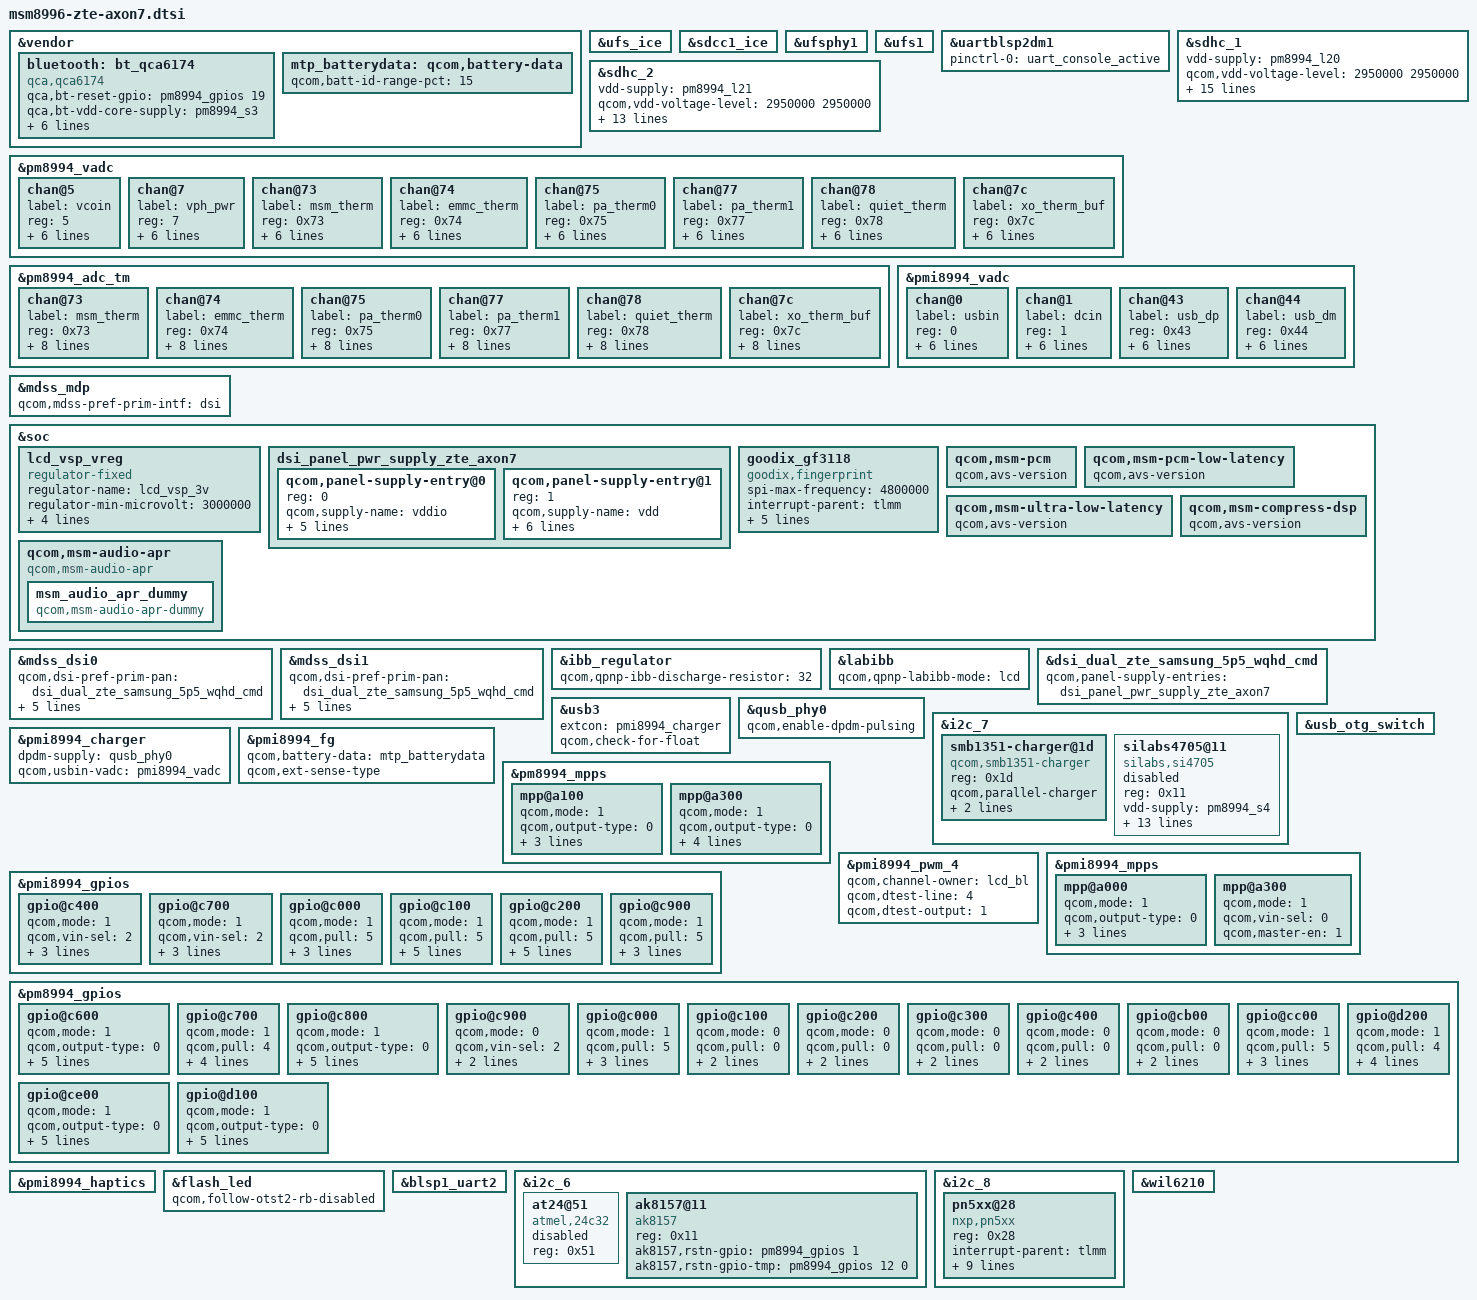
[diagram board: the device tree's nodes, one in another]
/* Copyright (c) 2015-2019, The Linux Foundation. All rights reserved.
 * Copyright (C) 2016 ZTE Corporation.
 *
 * This program is free software; you can redistribute it and/or modify
 * it under the terms of the GNU General Public License version 2 and
 * only version 2 as published by the Free Software Foundation.
 *
 * This program is distributed in the hope that it will be useful,
 * but WITHOUT ANY WARRANTY; without even the implied warranty of
 * MERCHANTABILITY or FITNESS FOR A PARTICULAR PURPOSE.  See the
 * GNU General Public License for more details.
 */

/*
 * ZTE Axon 7 (A2017G, ailsa_ii) board.
 *
 * ZTE built the Axon 7 board file by editing the CAF msm8996-mtp.dtsi of
 * their 3.18 kernel. This file is the 4.4 CAF msm8996-mtp.dtsi with the same
 * ZTE edits applied, so it can be compared with both. Left out from the MTP
 * file: the overrides for CAF reference panels and the TDM audio interfaces
 * (not used on this board), and the WCD9335 sound card (no WCD9335 here).
 * ZTE's changes to the shared SoC/PMIC files are in
 * msm8996-zte-axon7-common.dtsi.
 */

#include <dt-bindings/clock/msm-clocks-8996.h>
#include "msm8996-camera-sensor-zte-axon7.dtsi"
#include "msm8996-zte-axon7-typec.dtsi"
#include "msm8996-wsa881x.dtsi"

&vendor {
	bluetooth: bt_qca6174 {
		compatible = "qca,qca6174";
		qca,bt-reset-gpio = <&pm8994_gpios 19 0>; /* BT_EN */
		qca,bt-vdd-core-supply = <&pm8994_s3>;
		qca,bt-vdd-pa-supply = <&rome_vreg>;
		qca,bt-vdd-io-supply = <&pm8994_s4>;
		qca,bt-vdd-xtal-supply = <&pm8994_l30>;
		qca,bt-chip-pwd-voltage-level = <1300000 1300000>;
		qca,bt-vdd-io-voltage-level = <1800000 1800000>;
		qca,bt-vdd-xtal-voltage-level = <1800000 1800000>;
	};
};

&ufs_ice {
        status = "ok";
};

&sdcc1_ice {
        status = "ok";
};

&ufsphy1 {
	status = "ok";
};

&ufs1 {
	status = "ok";
};

&uartblsp2dm1 {
	status = "ok";
	pinctrl-names = "default";
	pinctrl-0 = <&uart_console_active>;

};

&sdhc_1 {
	vdd-supply = <&pm8994_l20>;
	qcom,vdd-voltage-level = <2950000 2950000>;
	qcom,vdd-current-level = <200 570000>;

	vdd-io-supply = <&pm8994_s4>;
	qcom,vdd-io-always-on;
	qcom,vdd-io-voltage-level = <1800000 1800000>;
	qcom,vdd-io-current-level = <110 325000>;

	pinctrl-names = "active", "sleep";
	pinctrl-0 = <&sdc1_clk_on &sdc1_cmd_on &sdc1_data_on &sdc1_rclk_on>;
	pinctrl-1 = <&sdc1_clk_off &sdc1_cmd_off &sdc1_data_off &sdc1_rclk_off>;

	qcom,clk-rates = <400000 20000000 25000000 50000000 96000000 192000000 384000000>;
	qcom,ice-clk-rates = <300000000 150000000>;
	qcom,nonremovable;
	qcom,bus-speed-mode = "HS400_1p8v", "HS200_1p8v", "DDR_1p8v";

	status = "ok";
};

&sdhc_2 {
	vdd-supply = <&pm8994_l21>;
	qcom,vdd-voltage-level = <2950000 2950000>;
	qcom,vdd-current-level = <200 800000>;

	vdd-io-supply = <&pm8994_l13>;
	qcom,vdd-io-voltage-level = <1800000 2950000>;
	qcom,vdd-io-current-level = <200 22000>;

	pinctrl-names = "active", "sleep";
	pinctrl-0 = <&sdc2_clk_on  &sdc2_cmd_on &sdc2_data_on &sdc2_cd_on>;
	pinctrl-1 = <&sdc2_clk_off &sdc2_cmd_off &sdc2_data_off &sdc2_cd_off>;

	qcom,clk-rates = <400000 20000000 25000000 50000000 100000000 200000000>;
	qcom,bus-speed-mode = "SDR12", "SDR25", "SDR50", "DDR50", "SDR104";

	cd-gpios = <&tlmm 95 0x0>;

	status = "ok";
};

&pm8994_vadc {
	chan@5 {
		label = "vcoin";
		reg = <5>;
		qcom,decimation = <0>;
		qcom,pre-div-channel-scaling = <1>;
		qcom,calibration-type = "absolute";
		qcom,scale-function = <0>;
		qcom,hw-settle-time = <0>;
		qcom,fast-avg-setup = <0>;
	};

	chan@7 {
		label = "vph_pwr";
		reg = <7>;
		qcom,decimation = <0>;
		qcom,pre-div-channel-scaling = <1>;
		qcom,calibration-type = "absolute";
		qcom,scale-function = <0>;
		qcom,hw-settle-time = <0>;
		qcom,fast-avg-setup = <0>;
	};

	chan@73 {
		label = "msm_therm";
		reg = <0x73>;
		qcom,decimation = <0>;
		qcom,pre-div-channel-scaling = <0>;
		qcom,calibration-type = "ratiometric";
		qcom,scale-function = <2>;
		qcom,hw-settle-time = <2>;
		qcom,fast-avg-setup = <0>;
	};

	chan@74 {
		label = "emmc_therm";
		reg = <0x74>;
		qcom,decimation = <0>;
		qcom,pre-div-channel-scaling = <0>;
		qcom,calibration-type = "ratiometric";
		qcom,scale-function = <2>;
		qcom,hw-settle-time = <2>;
		qcom,fast-avg-setup = <0>;
	};

	chan@75 {
		label = "pa_therm0";
		reg = <0x75>;
		qcom,decimation = <0>;
		qcom,pre-div-channel-scaling = <0>;
		qcom,calibration-type = "ratiometric";
		qcom,scale-function = <2>;
		qcom,hw-settle-time = <2>;
		qcom,fast-avg-setup = <0>;
	};

	chan@77 {
		label = "pa_therm1";
		reg = <0x77>;
		qcom,decimation = <0>;
		qcom,pre-div-channel-scaling = <0>;
		qcom,calibration-type = "ratiometric";
		qcom,scale-function = <2>;
		qcom,hw-settle-time = <2>;
		qcom,fast-avg-setup = <0>;
	};

	chan@78 {
		label = "quiet_therm";
		reg = <0x78>;
		qcom,decimation = <0>;
		qcom,pre-div-channel-scaling = <0>;
		qcom,calibration-type = "ratiometric";
		qcom,scale-function = <2>;
		qcom,hw-settle-time = <2>;
		qcom,fast-avg-setup = <0>;
	};

	chan@7c {
		label = "xo_therm_buf";
		reg = <0x7c>;
		qcom,decimation = <0>;
		qcom,pre-div-channel-scaling = <0>;
		qcom,calibration-type = "ratiometric";
		qcom,scale-function = <4>;
		qcom,hw-settle-time = <2>;
		qcom,fast-avg-setup = <0>;
	};
};

&pm8994_adc_tm {
	chan@73 {
		label = "msm_therm";
		reg = <0x73>;
		qcom,decimation = <0>;
		qcom,pre-div-channel-scaling = <0>;
		qcom,calibration-type = "ratiometric";
		qcom,scale-function = <2>;
		qcom,hw-settle-time = <2>;
		qcom,fast-avg-setup = <0>;
		qcom,btm-channel-number = <0x48>;
		qcom,thermal-node;
	};

	chan@74 {
		label = "emmc_therm";
		reg = <0x74>;
		qcom,decimation = <0>;
		qcom,pre-div-channel-scaling = <0>;
		qcom,calibration-type = "ratiometric";
		qcom,scale-function = <2>;
		qcom,hw-settle-time = <2>;
		qcom,fast-avg-setup = <0>;
		qcom,btm-channel-number = <0x68>;
		qcom,thermal-node;
	};

	chan@75 {
		label = "pa_therm0";
		reg = <0x75>;
		qcom,decimation = <0>;
		qcom,pre-div-channel-scaling = <0>;
		qcom,calibration-type = "ratiometric";
		qcom,scale-function = <2>;
		qcom,hw-settle-time = <2>;
		qcom,fast-avg-setup = <0>;
		qcom,btm-channel-number = <0x70>;
		qcom,thermal-node;
	};

	chan@77 {
		label = "pa_therm1";
		reg = <0x77>;
		qcom,decimation = <0>;
		qcom,pre-div-channel-scaling = <0>;
		qcom,calibration-type = "ratiometric";
		qcom,scale-function = <2>;
		qcom,hw-settle-time = <2>;
		qcom,fast-avg-setup = <0>;
		qcom,btm-channel-number = <0x78>;
		qcom,thermal-node;
	};

	chan@78 {
		label = "quiet_therm";
		reg = <0x78>;
		qcom,decimation = <0>;
		qcom,pre-div-channel-scaling = <0>;
		qcom,calibration-type = "ratiometric";
		qcom,scale-function = <2>;
		qcom,hw-settle-time = <2>;
		qcom,fast-avg-setup = <0>;
		qcom,btm-channel-number = <0x80>;
		qcom,thermal-node;
	};

	chan@7c {
		label = "xo_therm_buf";
		reg = <0x7c>;
		qcom,decimation = <0>;
		qcom,pre-div-channel-scaling = <0>;
		qcom,calibration-type = "ratiometric";
		qcom,scale-function = <4>;
		qcom,hw-settle-time = <2>;
		qcom,fast-avg-setup = <0>;
		qcom,btm-channel-number = <0x88>;
		qcom,thermal-node;
	};
};

&pmi8994_vadc {
	chan@0 {
		label = "usbin";
		reg = <0>;
		qcom,decimation = <0>;
		qcom,pre-div-channel-scaling = <4>;
		qcom,calibration-type = "absolute";
		qcom,scale-function = <0>;
		qcom,hw-settle-time = <0>;
		qcom,fast-avg-setup = <0>;
	};

	chan@1 {
		label = "dcin";
		reg = <1>;
		qcom,decimation = <0>;
		qcom,pre-div-channel-scaling = <4>;
		qcom,calibration-type = "absolute";
		qcom,scale-function = <0>;
		qcom,hw-settle-time = <0>;
		qcom,fast-avg-setup = <0>;
	};

	chan@43 {
		label = "usb_dp";
		reg = <0x43>;
		qcom,decimation = <0>;
		qcom,pre-div-channel-scaling = <1>;
		qcom,calibration-type = "absolute";
		qcom,scale-function = <0>;
		qcom,hw-settle-time = <0>;
		qcom,fast-avg-setup = <0>;
	};

	chan@44 {
		label = "usb_dm";
		reg = <0x44>;
		qcom,decimation = <0>;
		qcom,pre-div-channel-scaling = <1>;
		qcom,calibration-type = "absolute";
		qcom,scale-function = <0>;
		qcom,hw-settle-time = <0>;
		qcom,fast-avg-setup = <0>;
	};
};

#include "msm8996-mdss-panels.dtsi"
#include "dsi-panel-zte-samsung-s6e3ha3-5p5-wqhd-dualmipi-cmd.dtsi"

&mdss_mdp {
	qcom,mdss-pref-prim-intf = "dsi";
};

&soc {
	/*
	 * 3 V panel supply, switched by gpio 40 ("lcd 3v vsp"). ZTE's 3.18
	 * mdss driver toggled the gpio itself (zte,lcd-3v-vsp-enable-gpio);
	 * here it is a fixed regulator used as the panel "vdd" supply. The
	 * bootloader leaves it on for the splash screen.
	 */
	lcd_vsp_vreg: lcd_vsp_vreg {
		compatible = "regulator-fixed";
		regulator-name = "lcd_vsp_3v";
		regulator-min-microvolt = <3000000>;
		regulator-max-microvolt = <3000000>;
		gpio = <&tlmm 40 0>;
		enable-active-high;
		regulator-boot-on;
	};

	dsi_panel_pwr_supply_zte_axon7: dsi_panel_pwr_supply_zte_axon7 {
		#address-cells = <1>;
		#size-cells = <0>;

		qcom,panel-supply-entry@0 {
			reg = <0>;
			qcom,supply-name = "vddio";
			qcom,supply-min-voltage = <1800000>;
			qcom,supply-max-voltage = <1800000>;
			qcom,supply-enable-load = <62000>;
			qcom,supply-disable-load = <80>;
			qcom,supply-post-on-sleep = <20>;
		};

		/* ZTE: 5 ms after enable, 2 ms after disable */
		qcom,panel-supply-entry@1 {
			reg = <1>;
			qcom,supply-name = "vdd";
			qcom,supply-min-voltage = <3000000>;
			qcom,supply-max-voltage = <3000000>;
			qcom,supply-enable-load = <857000>;
			qcom,supply-disable-load = <0>;
			qcom,supply-post-on-sleep = <5>;
			qcom,supply-post-off-sleep = <2>;
		};
	};
};

&mdss_dsi0 {
	qcom,dsi-pref-prim-pan = <&dsi_dual_zte_samsung_5p5_wqhd_cmd>;
	pinctrl-names = "mdss_default", "mdss_sleep";
	pinctrl-0 = <&mdss_dsi_active &mdss_te_active>;
	pinctrl-1 = <&mdss_dsi_suspend &mdss_te_suspend>;
	qcom,platform-te-gpio = <&tlmm 10 0>;
	qcom,platform-reset-gpio = <&tlmm 8 0>;
	vdd-supply = <&lcd_vsp_vreg>;
};

&mdss_dsi1 {
	qcom,dsi-pref-prim-pan = <&dsi_dual_zte_samsung_5p5_wqhd_cmd>;
	pinctrl-names = "mdss_default", "mdss_sleep";
	pinctrl-0 = <&mdss_dsi_active &mdss_te_active>;
	pinctrl-1 = <&mdss_dsi_suspend &mdss_te_suspend>;
	qcom,platform-te-gpio = <&tlmm 10 0>;
	qcom,platform-reset-gpio = <&tlmm 8 0>;
	vdd-supply = <&lcd_vsp_vreg>;
};

&ibb_regulator {
	qcom,qpnp-ibb-discharge-resistor = <32>;
};

&labibb {
	status = "ok";
	qcom,qpnp-labibb-mode = "lcd";
};

&dsi_dual_zte_samsung_5p5_wqhd_cmd {
	qcom,panel-supply-entries = <&dsi_panel_pwr_supply_zte_axon7>;
};

&vendor {
	mtp_batterydata: qcom,battery-data {
		qcom,batt-id-range-pct = <15>;
		#include "batterydata-zte-p996a01-3250mah.dtsi"
	};
};

&usb3 {
	extcon = <&pmi8994_charger>;
	qcom,check-for-float;
};

&qusb_phy0 {
	qcom,enable-dpdm-pulsing;
};

&i2c_7 {
	smb1351-charger@1d {
		compatible = "qcom,smb1351-charger";
		reg = <0x1d>;
		qcom,parallel-charger;
		qcom,float-voltage-mv = <4400>;
		qcom,recharge-mv = <100>;
	};
};

&pmi8994_charger {
	dpdm-supply = <&qusb_phy0>;
	qcom,usbin-vadc = <&pmi8994_vadc>;
};

&pmi8994_fg {
	qcom,battery-data = <&mtp_batterydata>;
	qcom,ext-sense-type;
};

&usb_otg_switch {
	status = "okay";
};

&pm8994_mpps {
	mpp@a100 { /* MPP 2 */
		qcom,mode = <1>;		/* Digital output */
		qcom,output-type = <0>;		/* CMOS logic */
		qcom,vin-sel = <2>;		/* S4 1.8V */
		qcom,src-sel = <0>;		/* Constant */
		qcom,master-en = <1>;		/* Enable GPIO */
		status = "okay";
	};

	mpp@a300 { /* MPP 4 */
		/* HDMI_5v_vreg regulator enable */
		qcom,mode = <1>;		/* Digital output */
		qcom,output-type = <0>;		/* CMOS logic */
		qcom,vin-sel = <2>;		/* S4 1.8V */
		qcom,src-sel = <0>;		/* Constant */
		qcom,master-en = <1>;		/* Enable GPIO */
		qcom,invert = <1>;
		status = "okay";
	};
};

&pmi8994_gpios {
	gpio@c400 { /* GPIO 5 - USB3 OTG SWITCH EN */
		qcom,mode = <1>;	/* Digital output */
		qcom,vin-sel = <2>;	/* 1.8 */
		qcom,src-sel = <0>;	/* GPIO */
		qcom,master-en = <1>;	/* Enable GPIO */
		qcom,invert = <0>;	/* Output low initially */
		status = "okay";
	};
};

&pmi8994_gpios {
	gpio@c700 {	/* GPIO 8, lcd_reg_en, 5V boost  */
		qcom,mode = <1>;
		qcom,vin-sel = <2>;
		qcom,src-sel = <0>;
		qcom,invert = <1>;   /* need invert = 0 */
		qcom,master-en = <1>;
		status = "okay";
	};

	gpio@c000 {	/* GPIO 1  AK4490 PDN */
		qcom,mode = <1>;	/* DIGITAL OUT */
		qcom,pull = <5>;	/* No Pull */
		qcom,vin-sel = <2>;	/* 1.8 */
		qcom,src-sel = <0>;	/* CONSTANT */
		qcom,master-en = <1>;	/* ENABLE GPIO */
		status = "okay";
	};

	gpio@c100 {	/* GPIO 2  SMART PA RST1 */
		qcom,mode = <1>;	/* DIGITAL OUT */
		qcom,pull = <5>;	/* No Pull */
		qcom,vin-sel = <2>;	/* 1.8 */
		qcom,src-sel = <0>;	/* CONSTANT */
		qcom,invert = <0>;	/* Output low initially */
		qcom,out-strength = <1>;	/* Low drive strength */
		qcom,master-en = <1>;	/* ENABLE GPIO */
		status = "okay";
	};

	gpio@c200 {	/* GPIO 3 SMART PA RST2 */
		qcom,mode = <1>;	/* DIGITAL OUT */
		qcom,pull = <5>;	/* No Pull */
		qcom,vin-sel = <2>;	/* 1.8 */
		qcom,src-sel = <0>;	/* CONSTANT */
		qcom,invert = <0>;	/* Output low initially */
		qcom,out-strength = <1>;	/* Low drive strength */
		qcom,master-en = <1>;	/* ENABLE GPIO */
		status = "okay";
	};

	gpio@c900 { /* GPIO 10 - ISL98608 power switch */
		qcom,mode = <1>;
		qcom,pull = <5>;
		qcom,vin-sel = <2>;
		qcom,src-sel = <0>;
		qcom,master-en = <1>;
		status = "okay";
	};
};

&pmi8994_pwm_4 {
	qcom,channel-owner = "lcd_bl";
	qcom,dtest-line = <4>;
	qcom,dtest-output = <1>;
	status = "okay";
};

&pmi8994_mpps {
	mpp@a000 { /* MPP 1 */
		qcom,mode = <1>;                /* Digital output */
		qcom,output-type = <0>;         /* CMOS logic */
		qcom,vin-sel = <2>;             /* S4 1.8V */
		qcom,src-sel = <7>;             /* DTEST4 */
		qcom,master-en = <1>;           /* Enable MPP */
		status = "okay";
	};

	mpp@a300 { /* MPP 4 */
		/* WLED FET */
		qcom,mode = <1>;        /* DIGITAL OUT */
		qcom,vin-sel = <0>;     /* VIN0 */
		qcom,master-en = <1>;
		status = "okay";
	};
};

&soc {
	/* Goodix GF3118M fingerprint sensor (drivers/input/fingerprint/goodix; the TEE reads the sensor) */
	goodix_gf3118 {
		compatible = "goodix,fingerprint";
		spi-max-frequency = <4800000>;
		interrupt-parent = <&tlmm>;
		interrupts = <123 0x0>;
		goodix,gpio_pwr = <&tlmm 85 0>;
		goodix,gpio_reset = <&tlmm 39 0>;
		goodix,gpio_id = <&tlmm 21 0>;
		goodix,gpio_irq = <&tlmm 123 0>;
	};

	qcom,msm-pcm {
		qcom,avs-version;
	};

	qcom,msm-pcm-low-latency {
		qcom,avs-version;
	};

	qcom,msm-ultra-low-latency {
		qcom,avs-version;
	};

	qcom,msm-compress-dsp {
		qcom,avs-version;
	};

	qcom,msm-audio-apr {
		compatible = "qcom,msm-audio-apr";
		msm_audio_apr_dummy {
			compatible = "qcom,msm-audio-apr-dummy";

		};
	};
};

&pm8994_gpios {
	gpio@c600 { /* GPIO 7 - NFC DWL REQ */
		qcom,mode = <1>;
		qcom,output-type = <0>;
		qcom,pull = <5>;
		qcom,vin-sel = <2>;
		qcom,out-strength = <3>;
		qcom,src-sel = <0>;
		qcom,master-en = <1>;
		status = "okay";
	};

	gpio@c700 { /* GPIO 8 - WLAN_EN */
		qcom,mode = <1>;		/* Digital output*/
		qcom,pull = <4>;		/* Pulldown 10uA */
		qcom,vin-sel = <2>;		/* VIN2 */
		qcom,src-sel = <0>;		/* GPIO */
		qcom,invert = <0>;		/* Invert */
		qcom,master-en = <1>;		/* Enable GPIO */
		status = "okay";
	};

	gpio@c800 { /* GPIO 9 - Rome 3.3V control */
		qcom,mode = <1>;		/* Digital output */
		qcom,output-type = <0>;		/* MOS logic */
		qcom,invert = <1>;		/* Output high */
		qcom,vin-sel = <0>;		/* VPH_PWR */
		qcom,src-sel = <0>;		/* Constant */
		qcom,out-strength = <1>;	/* High drive strength */
		qcom,master-en = <1>;		/* Enable GPIO */
		status = "okay";
	};

	gpio@c900 { /* GPIO 10 - NFC CLK _REQ*/
		qcom,mode = <0>;
		qcom,vin-sel = <2>;
		qcom,src-sel = <0>;
		qcom,master-en = <1>;
		status = "okay";
	};

	/* GPIO 14 is the Type-C controller interrupt, see the typec dtsi */

	gpio@c000 { /* GPIO 1 - AK8157 RSTN */
		qcom,mode = <1>;
		qcom,pull = <5>;
		qcom,vin-sel = <2>;
		qcom,src-sel = <0>;
		qcom,master-en = <1>;
		status = "okay";
	};

	gpio@c100 { /* GPIO 2 - volume down key */
		qcom,mode = <0>;
		qcom,pull = <0>;
		qcom,vin-sel = <2>;
		qcom,src-sel = <0>;
		status = "okay";
	};

	gpio@c200 { /* GPIO 3 - volume up key */
		qcom,mode = <0>;
		qcom,pull = <0>;
		qcom,vin-sel = <2>;
		qcom,src-sel = <0>;
		status = "okay";
	};

	gpio@c300 { /* GPIO 4 */
		qcom,mode = <0>;
		qcom,pull = <0>;
		qcom,vin-sel = <2>;
		qcom,src-sel = <0>;
		status = "okay";
	};

	gpio@c400 { /* GPIO 5 */
		qcom,mode = <0>;
		qcom,pull = <0>;
		qcom,vin-sel = <2>;
		qcom,src-sel = <0>;
		status = "okay";
	};

	gpio@cb00 { /* GPIO 12 - AK8157 RSTN (alternate) */
		qcom,mode = <0>;
		qcom,pull = <0>;
		qcom,vin-sel = <2>;
		qcom,src-sel = <0>;
		status = "okay";
	};

	gpio@cc00 { /* GPIO 13 - RCV_SPK_SWITCH */
		qcom,mode = <1>;
		qcom,pull = <5>;
		qcom,vin-sel = <2>;
		qcom,src-sel = <0>;
		qcom,master-en = <1>;
		status = "okay";
	};

	gpio@ce00 { /* GPIO 15 */
		qcom,mode = <1>;
		qcom,output-type = <0>;
		qcom,pull = <5>;
		qcom,vin-sel = <2>;
		qcom,out-strength = <1>;
		qcom,src-sel = <2>;
		qcom,master-en = <1>;
		status = "okay";
	};

	gpio@d100 { /* GPIO 18 - Rome Sleep Clock */
		qcom,mode = <1>;		/* Digital output */
		qcom,output-type = <0>;		/* CMOS logic */
		qcom,invert = <0>;		/* Output low initially */
		qcom,vin-sel = <2>;		/* VIN 2 */
		qcom,src-sel = <3>;		/* Function 2 */
		qcom,out-strength = <2>;	/* Medium */
		qcom,master-en = <1>;		/* Enable GPIO */
		status = "okay";
	};

	gpio@d200 { /* GPIO 19 - Rome BT Reset */
		qcom,mode = <1>;		/* Digital output*/
		qcom,pull = <4>;		/* Pulldown 10uA */
		qcom,vin-sel = <2>;		/* VIN2 */
		qcom,src-sel = <0>;		/* GPIO */
		qcom,invert = <0>;		/* Invert */
		qcom,master-en = <1>;		/* Enable GPIO */
		status = "okay";
	};
};

&pmi8994_haptics {
	status = "okay";
};

&flash_led {
	qcom,follow-otst2-rb-disabled;
};

&blsp1_uart2 {
	status = "ok";
};

&i2c_6 {
	at24@51 {
		status = "disabled";
		compatible = "atmel,24c32";
		reg = <0x51>;
	};

	/* AKM AK8157 audio PLL (no driver yet) */
	ak8157@11 {
		compatible = "ak8157";
		reg = <0x11>;
		ak8157,rstn-gpio = <&pm8994_gpios 1 0>;
		ak8157,rstn-gpio-tmp = <&pm8994_gpios 12 0>;
	};
};

&i2c_7 {
	silabs4705@11 { /* SiLabs FM chip, slave id 0x11*/
		status = "disabled";	/* not fitted, gpio 38 is used by the camera */
		compatible = "silabs,si4705";
		reg = <0x11>;
		vdd-supply = <&pm8994_s4>;
		silabs,vdd-supply-voltage = <1800000 1800000>;
		va-supply = <&rome_vreg>;
		silabs,va-supply-voltage = <3300000 3300000>;
		pinctrl-names = "pmx_fm_active","pmx_fm_suspend";
		pinctrl-0 = <&fm_int_active &fm_status_int_active &fm_rst_active>;
		pinctrl-1 = <&fm_int_suspend &fm_status_int_suspend &fm_rst_suspend>;
		silabs,reset-gpio = <&tlmm 39 0>;
		silabs,int-gpio = <&tlmm 38 0>;
		silabs,status-gpio = <&tlmm 78 0>;
		#address-cells = <0>;
		interrupts = <0 1>;
		#interrupt-cells = <1>;
		interrupt-map-mask = <0xffffffff>;
		interrupt-map = <
				  0 &tlmm 38 2
				  1 &tlmm 78 1
				>;
		interrupt-names = "silabs_fm_int", "silabs_fm_status_int";
	};
};

&i2c_8 { /* BLSP2 QUP2 */
	/* NXP PN548 NFC. nxp,pn5xx binding of ZTE's pn5xx_i2c driver (not ported) */
	pn5xx@28 {
		compatible = "nxp,pn5xx";
		reg = <0x28>;
		interrupt-parent = <&tlmm>;
		interrupts = <9 0>;
		nxp,pn5xx-irq = <&tlmm 9 0x00>;
		nxp,pn5xx-ven = <&tlmm 12 0x00>;
		nxp,pn5xx-fw-dwnld = <&tlmm 96 0x00>;
		nxp,pn5xx-ese-pwr = <&pm8994_gpios 7 0x00>;
		nxp,int_active_low = <0>;
		pinctrl-names = "nfc_active", "nfc_suspend";
		pinctrl-0 = <&nfc_int_active &nfc_disable_active>;
		pinctrl-1 = <&nfc_int_suspend &nfc_disable_suspend>;
	};
};

&wil6210 {
	status = "ok";
};
